# AT32WB415xx_v2 register map
Vendor: Keil; Series: AT32WB415; File version: 1.0
CPU: CM4 r0p1, little endian, no MPU, FPU, 4 interrupt priority bits
Registers are 32-bit, read-write, reset 0x0 unless marked. A register's access mark holds for its fields unless they carry their own. Offsets are from the block's base; [hi:lo] are bit positions; {n}, {i} and the like mark numbered series.

## EXINT
Base 0x40010400
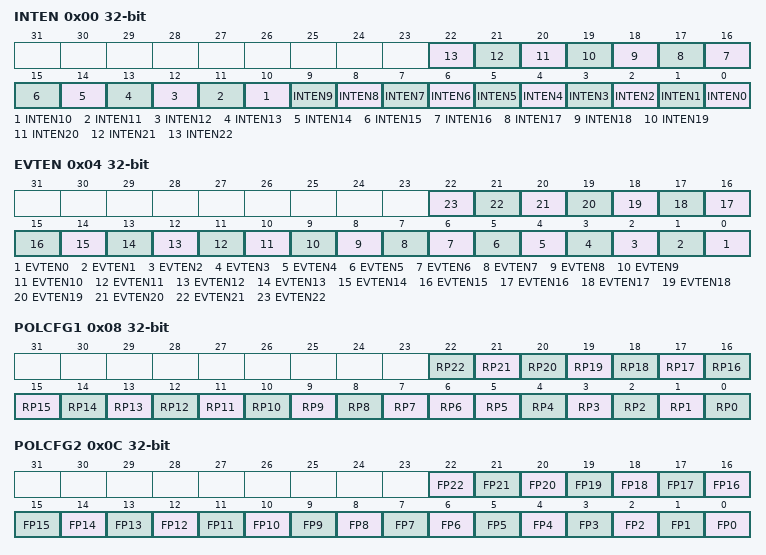
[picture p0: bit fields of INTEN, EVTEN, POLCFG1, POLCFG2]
0x00 INTEN — Interrupt enable register
  [n] INTEN{n} (n=0..22) — Interrupt enable or disable on line {n}
0x04 EVTEN — Event enable register
  [n] EVTEN{n} (n=0..22) — Event enable or disable on line {n}
0x08 POLCFG1 — Rising polarity configuration register
  [n] RP{n} (n=7..22) — Rising polarity configuration bit of line {n}
  [6] RP6 — Rising polarity configuration bit of linee 6
  [n] RP{n} (n=0..5) — Rising polarity configuration bit of line {n}
0x0C POLCFG2 — Falling polarity configuration register
  [n] FP{n} (n=0..22) — Falling polarity event configuration bit of line {n}
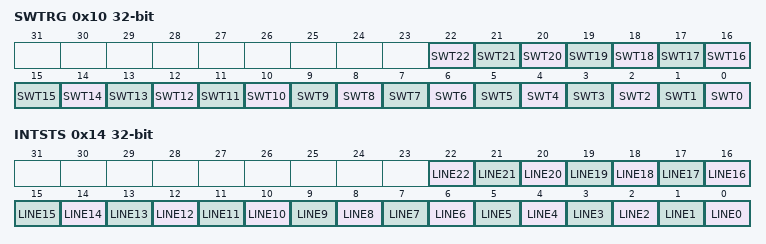
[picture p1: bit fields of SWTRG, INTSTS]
0x10 SWTRG — Software triggle register
  [n] SWT{n} (n=0..22) — Software triggle on line {n}
0x14 INTSTS — Interrupt status register
  [n] LINE{n} (n=0..22) — Line {n} state bit

## ACC — HICK Auto Clock Calibration
Base 0x40015800
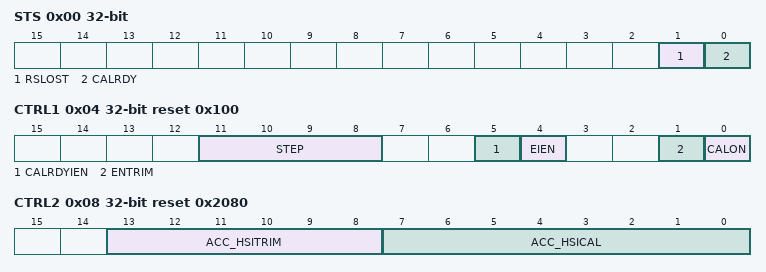
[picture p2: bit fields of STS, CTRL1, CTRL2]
0x00 STS — Status register
  [1] RSLOST — Reference Signal Lost
  [0] CALRDY — Internal high-speed clock calibration ready
0x04 CTRL1 reset 0x100 — Control register 1
  [11:8] STEP
  [5] CALRDYIEN — CALRDY interrupt enable
  [4] EIEN — RSLOST error interrupt enable
  [1] ENTRIM — Enable trim
  [0] CALON — Internal high-speed clock calibration ready
0x08 CTRL2 ro reset 0x2080 — Control register 2
  [13:8] ACC_HSITRIM — Internal high-speed auto clock trimming
  [7:0] ACC_HSICAL — Internal high-speed auto clock calibration
0x0C C1 reset 0x1F2C — Compare 1
  [15:0] C1
0x10 C2 reset 0x1F40 — Compare 2
  [15:0] C2
0x14 C3 reset 0x1F54 — Compare 3
  [15:0] C3

## WDT — Watchdog
Base 0x40003000
0x00 CMD — Command register
  [15:0] CMD
0x04 DIV — Division register
  [2:0] DIV — Division divider
0x08 RLD reset 0xFFF — Reload register
  [11:0] RLD — Reload value
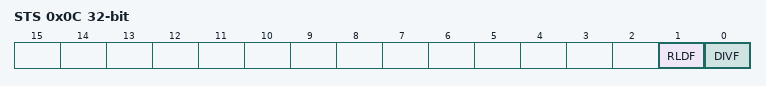
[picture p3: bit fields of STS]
0x0C STS — Status register
  [1] RLDF — Reload value update complete flag
  [0] DIVF — Division value update complete flag

## WWDT — Window watchdog
Base 0x40002C00
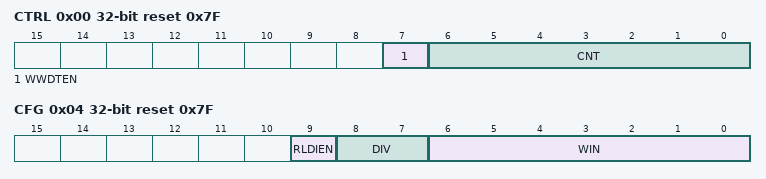
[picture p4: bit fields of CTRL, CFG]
0x00 CTRL reset 0x7F — Control register
  [7] WWDTEN — Window watchdog enable
  [6:0] CNT — Decrement counter
0x04 CFG reset 0x7F — Configuration register
  [9] RLDIEN — Reload counter interrupt
  [8:7] DIV — Clock division value
  [6:0] WIN — Window value
0x08 STS — Status register
  [0] RLDF — Reload counter interrupt flag

## TMR9 — General purpose timer
Base 0x40014C00
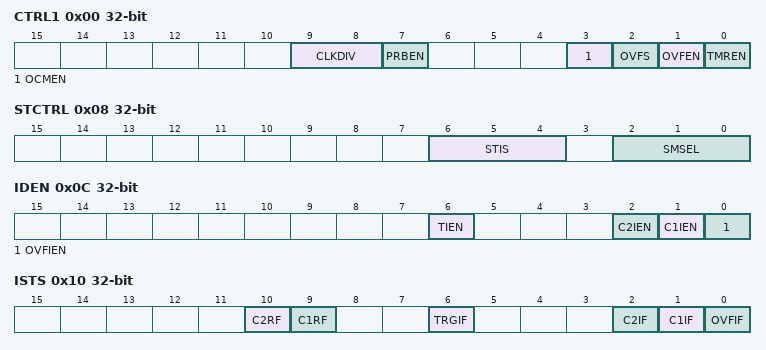
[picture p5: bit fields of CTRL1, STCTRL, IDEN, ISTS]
0x00 CTRL1 — Control register 1
  [9:8] CLKDIV — Clock divider
  [7] PRBEN — Period buffer enable
  [3] OCMEN — One cycle mode enable
  [2] OVFS — Overflow event source
  [1] OVFEN — Overflow event enable
  [0] TMREN — TMR enable
0x08 STCTRL — Subordinate TMR control register
  [6:4] STIS — Subordinate TMR input selection
  [2:0] SMSEL — Subordinate TMR mode selection
0x0C IDEN — Interrupt/DMA enable register
  [6] TIEN — Trigger interrupt enable
  [2] C2IEN — Channel 2 interrupt enable
  [1] C1IEN — Channel 1 interrupt enable
  [0] OVFIEN — Overflow interrupt enable
0x10 ISTS — Interrupt status register
  [10] C2RF — Channel 2 recapture flag
  [9] C1RF — Channel 1 recapture flag
  [6] TRGIF — Trigger interrupt flag
  [2] C2IF — Channel 2 interrupt flag
  [1] C1IF — Channel 1 interrupt flag
  [0] OVFIF — Overflow interrupt flag
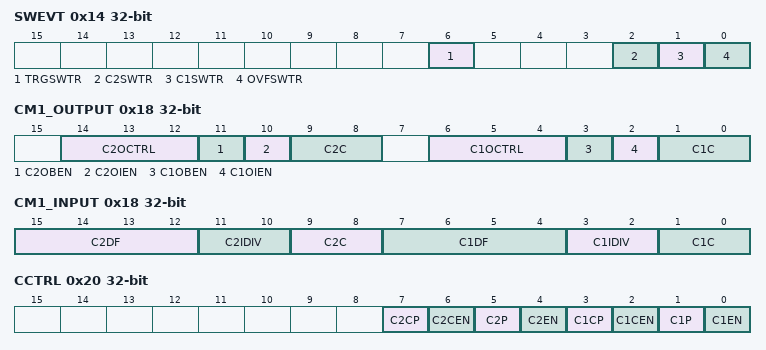
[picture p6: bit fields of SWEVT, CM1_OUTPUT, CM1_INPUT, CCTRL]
0x14 SWEVT — Software event register
  [6] TRGSWTR — Trigger event triggered by software
  [2] C2SWTR — Channel 2 event triggered by software
  [1] C1SWTR — Channel 1 event triggered by software
  [0] OVFSWTR — Overflow event triggered by software
0x18 CM1_OUTPUT — Channel output mode register
  [14:12] C2OCTRL — Channel 2 output control
  [11] C2OBEN — Channel 2 output buffer enable
  [10] C2OIEN — Channel 2 output immediately enable
  [9:8] C2C — Channel 2 configure
  [6:4] C1OCTRL — Channel 1 output control
  [3] C1OBEN — Channel 1 output buffer enable
  [2] C1OIEN — Channel 1 output immediately enable
  [1:0] C1C — Channel 1 configure
0x18 CM1_INPUT (alternate view of CM1_OUTPUT) — Channel input mode register 1
  [15:12] C2DF — Channel 2 digital filter
  [11:10] C2IDIV — Channel 2 input divider
  [9:8] C2C — Channel 2 configure
  [7:4] C1DF — Channel 1 digital filter
  [3:2] C1IDIV — Channel 1 input divider
  [1:0] C1C — Channel 1 configure
0x20 CCTRL — Channel control register
  [7] C2CP — Channel 2 complementary polarity
  [6] C2CEN — Channel 2 complementary enable
  [5] C2P — Channel 2 Polarity
  [4] C2EN — Channel 2 enable
  [3] C1CP — Channel 1 complementary polarity
  [2] C1CEN — Channel 1 complementary enable
  [1] C1P — Channel 1 Polarity
  [0] C1EN — Channel 1 enable
0x24 CVAL — Counter value
  [15:0] CVAL
0x28 DIV — Divider value
  [15:0] DIV
0x2C PR — Period value
  [15:0] PR
0x34 C1DT — Channel 1 data register
  [15:0] C1DT
0x38 C2DT — Channel 2 data register
  [15:0] C2DT

## Notices in the file
Copyright (C) 2012-2014 ARM Limited. All rights reserved.
Purpose: System Viewer Description (SVD) Example (Schema Version 1.1)
This is a description of a none-existent and incomplete device
for demonstration purposes only.
Redistribution and use in source and binary forms, with or without
modification, are permitted provided that the following conditions are met:
- Redistributions of source code must retain the above copyright
notice, this list of conditions and the following disclaimer.
- Redistributions in binary form must reproduce the above copyright
notice, this list of conditions and the following disclaimer in the
documentation and/or other materials provided with the distribution.
- Neither the name of ARM nor the names of its contributors may be used
to endorse or promote products derived from this software without
specific prior written permission.
THIS SOFTWARE IS PROVIDED BY THE COPYRIGHT HOLDERS AND CONTRIBUTORS "AS IS"
AND ANY EXPRESS OR IMPLIED WARRANTIES, INCLUDING, BUT NOT LIMITED TO, THE
IMPLIED WARRANTIES OF MERCHANTABILITY AND FITNESS FOR A PARTICULAR PURPOSE
ARE DISCLAIMED. IN NO EVENT SHALL COPYRIGHT HOLDERS AND CONTRIBUTORS BE
LIABLE FOR ANY DIRECT, INDIRECT, INCIDENTAL, SPECIAL, EXEMPLARY, OR
CONSEQUENTIAL DAMAGES (INCLUDING, BUT NOT LIMITED TO, PROCUREMENT OF
SUBSTITUTE GOODS OR SERVICES; LOSS OF USE, DATA, OR PROFITS; OR BUSINESS
INTERRUPTION) HOWEVER CAUSED AND ON ANY THEORY OF LIABILITY, WHETHER IN
CONTRACT, STRICT LIABILITY, OR TORT (INCLUDING NEGLIGENCE OR OTHERWISE)
ARISING IN ANY WAY OUT OF THE USE OF THIS SOFTWARE, EVEN IF ADVISED OF THE
POSSIBILITY OF SUCH DAMAGE.
